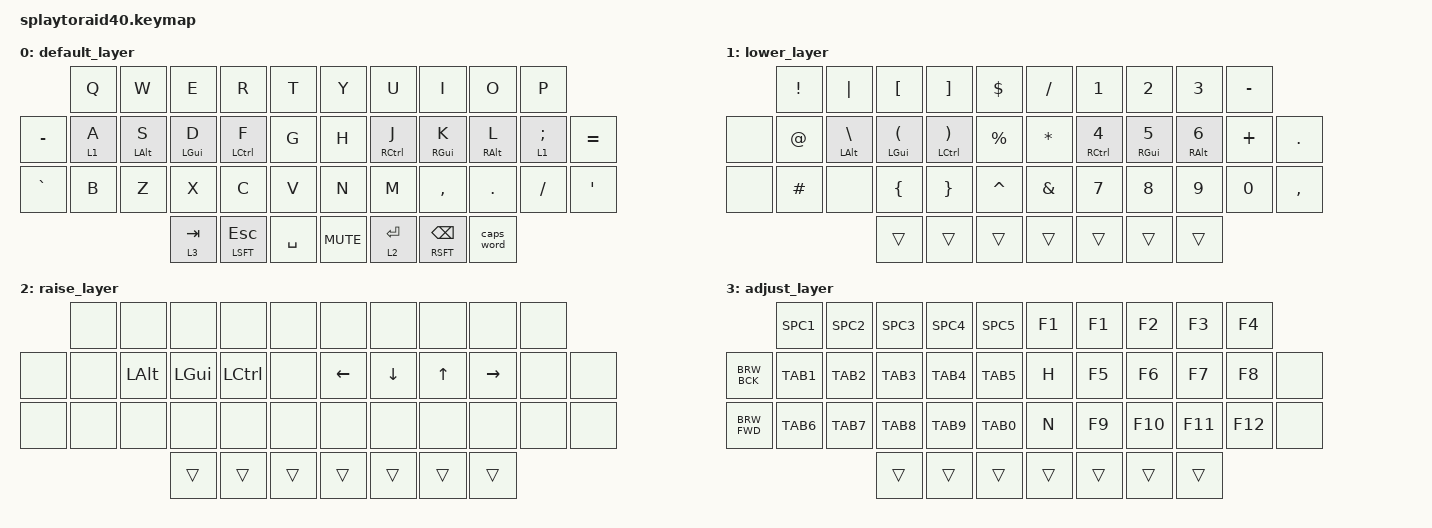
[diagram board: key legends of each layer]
/*
 * Copyright (c) 2021 The ZMK Contributors
 *
 * SPDX-License-Identifier: MIT
 */

#include <behaviors.dtsi>
#include <dt-bindings/zmk/behaviors.h>
#include <dt-bindings/zmk/keys.h>
#include <dt-bindings/zmk/bt.h>
#include <dt-bindings/zmk/outputs.h>
#include <dt-bindings/zmk/rgb.h>

#define LEFT_KEYS <0 1 2 3 4 10 11 12 13 14 15 22 23 24 25 26 27>
#define RIGHT_KEYS <5 6 7 8 9 16 17 18 19 20 21 28 29 30 31 32 33>

&caps_word {
    continue-list = <UNDERSCORE MINUS BSPC LSHFT RSHFT>;
};
/ {
    behaviors {
        hml: home_row_mod_left {
            compatible = "zmk,behavior-hold-tap";
            #binding-cells = <2>;
            bindings = <&kp>, <&kp>;
            flavor = "balanced";
            require-prior-idle-ms = <150>;
            tapping-term-ms = <280>;
            quick-tap-ms = <175>;
            hold-trigger-key-positions = RIGHT_KEYS;
            hold-trigger-on-release;
        };
        hll: home_row_layer_left {
            compatible = "zmk,behavior-hold-tap";
            #binding-cells = <2>;
            bindings = <&mo>, <&kp>;
            flavor = "balanced";
            require-prior-idle-ms = <150>;
            tapping-term-ms = <280>;
            quick-tap-ms = <175>;
            hold-trigger-key-positions = RIGHT_KEYS;
            hold-trigger-on-release;
        };
        hmr: home_row_mod_right {
            compatible = "zmk,behavior-hold-tap";
            #binding-cells = <2>;
            bindings = <&kp>, <&kp>;
            flavor = "balanced";
            require-prior-idle-ms = <150>;
            tapping-term-ms = <280>;
            quick-tap-ms = <175>;
            hold-trigger-key-positions = LEFT_KEYS; 
            hold-trigger-on-release;
        };
        hlr: home_row_layer_right {
            compatible = "zmk,behavior-hold-tap";
            #binding-cells = <2>;
            bindings = <&mo>, <&kp>;
            flavor = "balanced";
            require-prior-idle-ms = <150>;
            tapping-term-ms = <280>;
            quick-tap-ms = <175>;
            hold-trigger-key-positions = LEFT_KEYS;
            hold-trigger-on-release;
        };
        mt: mod_tap {
            compatible = "zmk,behavior-hold-tap";
            #binding-cells = <2>;
            bindings = <&kp>, <&kp>;
            flavor = "hold-preferred";
            tapping-term-ms = <175>;
            display-name = "Mod-Tap";
        };
        lt: layer_tap {
            compatible = "zmk,behavior-hold-tap";
            #binding-cells = <2>;
            bindings = <&mo>, <&kp>;
            flavor = "hold-preferred";
            tapping-term-ms = <175>;
            display-name = "Layer-Tap";
        };
    };
};

#define SPC1 LC(LG(N1))
#define SPC2 LC(LG(N2))
#define SPC3 LC(LG(N3))
#define SPC4 LC(LG(N4))
#define SPC5 LC(LG(N5))

#define TAB1 LG(N1)
#define TAB2 LG(N2)
#define TAB3 LG(N3)
#define TAB4 LG(N4)
#define TAB5 LG(N5)
#define TAB6 LG(N6)
#define TAB7 LG(N7)
#define TAB8 LG(N8)
#define TAB9 LG(N9)
#define TAB0 LG(N0)

#define BRW_BCK LG(LEFT)
#define BRW_FWD LG(RIGHT)

/ {
    keymap {
        compatible = "zmk,keymap";
        default_layer {
            bindings = <
                    &kp Q    &kp W       &kp E       &kp R       &kp T    /**/      &kp Y     &kp U       &kp I       &kp O       &kp P 
         &kp MINUS  &hll 1 A &hml LALT S &hml LGUI D &hml LCTL F &kp G    /**/      &kp H     &hmr RCTL J &hmr RGUI K &hmr RALT L &hlr 1 SEMI &kp EQUAL
         &kp GRAVE  &kp B    &kp Z       &kp X       &kp C       &kp V    /**/      &kp N     &kp M       &kp COMMA   &kp DOT     &kp SLASH   &kp APOS
                                         &lt 3 TAB   &mt LSFT ESC&kp SPC &kp C_MUTE &lt 2 RET &mt RSFT BSPC&caps_word
            >;
            sensor-bindings = <&inc_dec_kp C_VOL_DN C_VOL_UP>;
        };
        lower_layer {
            bindings = <
                    &kp EXCL &kp PIPE       &kp LBKT       &kp RBKT       &kp DLLR /**/      &kp SLASH &kp N1      &kp N2      &kp N3      &kp MINUS
         &none      &kp AT   &hml LALT BSLH &hml LGUI LPAR &hml LCTL RPAR &kp PRCNT/**/      &kp STAR  &hmr RCTL N4&hmr RGUI N5&hmr RALT N6&kp PLUS    &kp DOT  
         &none      &kp HASH &none          &kp LBRC       &kp RBRC       &kp CARET/**/      &kp AMPS  &kp N7      &kp N8      &kp N9      &kp N0      &kp COMMA
                                         &trans      &trans      &trans  &trans     &trans    &trans       &trans    
            >;
        };
        raise_layer {
            bindings = <
                    &none    &none       &none       &none       &none    /**/      &none     &none       &none       &none       &none 
         &none      &none    &kp LALT    &kp LGUI    &kp LCTL    &none    /**/      &kp LEFT  &kp DOWN    &kp UP      &kp RIGHT   &none       &none      
         &none      &none    &none       &none       &none       &none    /**/      &none     &none       &none       &none       &none       &none      
                                         &trans      &trans      &trans  &trans     &trans    &trans       &trans    
            >;
        };
        adjust_layer {
            bindings = <
                     &kp SPC1 &kp SPC2 &kp SPC3 &kp SPC4 &kp SPC5 /**/      &kp F1    &kp F1      &kp F2      &kp F3      &kp F4
         &kp BRW_BCK&kp TAB1 &kp TAB2 &kp TAB3 &kp TAB4 &kp TAB5 /**/      &kp H     &kp F5      &kp F6      &kp F7      &kp F8      &none
         &kp BRW_FWD&kp TAB6 &kp TAB7 &kp TAB8 &kp TAB9 &kp TAB0 /**/      &kp N     &kp F9      &kp F10     &kp F11     &kp F12     &none
                                         &trans      &trans      &trans  &trans     &trans    &trans       &trans    
            >;
        };
    };
};
